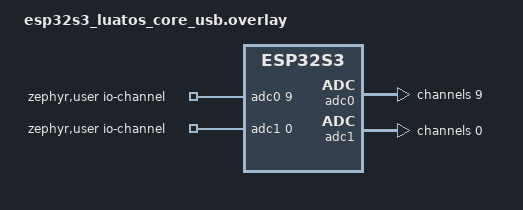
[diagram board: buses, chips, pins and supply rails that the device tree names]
/*
 * Copyright (c) 2022 Wolter HV <wolterhv@gmx.de>
 *
 * SPDX-License-Identifier: Apache-2.0
 */

 / {
	 zephyr,user {
		 io-channels = <&adc0 9>, <&adc1 0>;
	 };
 };

 &adc0 {
	 status = "okay";
	 #address-cells = <1>;
	 #size-cells = <0>;

	 channel@9 {
		 reg = <9>;
		 zephyr,gain = "ADC_GAIN_1_4";
		 zephyr,reference = "ADC_REF_INTERNAL";
		 zephyr,acquisition-time = <ADC_ACQ_TIME_DEFAULT>;
		 zephyr,resolution = <12>;
	 };
 };

 &adc1 {
	 status = "okay";
	 #address-cells = <1>;
	 #size-cells = <0>;

	 channel@0 {
		 reg = <0>;
		 zephyr,gain = "ADC_GAIN_1_4";
		 zephyr,reference = "ADC_REF_INTERNAL";
		 zephyr,acquisition-time = <ADC_ACQ_TIME_DEFAULT>;
		 zephyr,resolution = <12>;
	 };
 };
